# COREAON_CM_CORE register map
Vendor: Texas Instruments
Peripheral module from a debugger description file (folder omap5430_ES2_PUBLIC).
Registers are 32-bit, access per field, reset 0x30000 unless marked. A register's access mark holds for its fields unless they carry their own. Offsets are as the file gives them; lines under a group give offsets from that group; [hi:lo] are bit positions; {n}, {i} and the like mark numbered series; 'fields as' and 'values as' point back to an identical list; <NAME> marks a mode.

## COREAON_CM_CORE
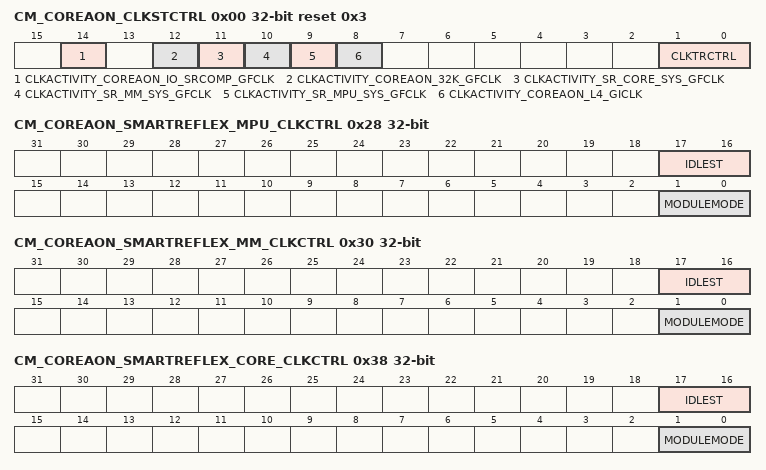
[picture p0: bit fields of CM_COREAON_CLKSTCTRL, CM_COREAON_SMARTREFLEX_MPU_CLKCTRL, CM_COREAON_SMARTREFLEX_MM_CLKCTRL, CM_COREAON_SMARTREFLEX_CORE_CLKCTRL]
0x00 CM_COREAON_CLKSTCTRL reset 0x3 — This register enables the domain power state transition. It controls the HW supervised domain power state transition between ON-ACTIVE and ON-INACTIVE states. It also holds 1 status bit per clock input of the domain.
  [14] CLKACTIVITY_COREAON_IO_SRCOMP_GFCLK ro — This field indicates the state of the COREAON_IO_SRCOMP_GFCLK clock in the domain. [warm reset insensitive] Read 0x0: Corresponding clock is definitely gated Read 0x1: Corresponding clock is running or gating/ungating transition is on-going
  [12] CLKACTIVITY_COREAON_32K_GFCLK ro — This field indicates the state of the COREAON_32K_GFCLK clock in the domain. [warm reset insensitive] Read 0x0: Corresponding clock is definitely gated Read 0x1: Corresponding clock is running or gating/ungating transition is on-going
  [11] CLKACTIVITY_SR_CORE_SYS_GFCLK ro — This field indicates the state of the SR_CORE_SYS_GFCLK clock input of the domain. [warm reset insensitive]
    0=Inact (Corresponding clock is definitely gated); 1=Act (Corresponding clock is running or gating/ungating transition is on-going)
  [10] CLKACTIVITY_SR_MM_SYS_GFCLK ro — This field indicates the state of the SR_MM_SYS_GFCLK clock input of the domain. [warm reset insensitive]
    values as CLKACTIVITY_SR_CORE_SYS_GFCLK
  [9] CLKACTIVITY_SR_MPU_SYS_GFCLK ro — This field indicates the state of the SR_MPU_SYS_GFCLK clock input of the domain. [warm reset insensitive]
    values as CLKACTIVITY_SR_CORE_SYS_GFCLK
  [8] CLKACTIVITY_COREAON_L4_GICLK ro — This field indicates the state of the COREAON_L4_GICLK clock of the domain. [warm reset insensitive]
    values as CLKACTIVITY_SR_CORE_SYS_GFCLK
  [1:0] CLKTRCTRL rw — Controls the clock state transition of the COREAON clock domain.
    0=NO_SLEEP (NO_SLEEP: Sleep transition cannot be initiated. Wakeup transition may however occur.); 2=SW_WKUP (SW_WKUP: Start a software forced wake-up transition on the domain.); 3=HW_AUTO (HW_AUTO: Automatic transition is enabled. Sleep and wakeup transition are based upon hardware conditions.)
0x28 CM_COREAON_SMARTREFLEX_MPU_CLKCTRL — This register manages the SMARTREFLEX_MPU clocks.
  [17:16] IDLEST ro — Module idle status. [warm reset insensitive]
    0=Func (Module is fully functional, including INTRCONN); 1=Trans (Module is performing transition: wakeup, or sleep, or sleep abortion); 2=Idle (Module is in Idle mode (only INTRCONN part). It is functional if using separate functional clock); 3=Disable (Module is disabled and cannot be accessed)
  [1:0] MODULEMODE rw — Control the way mandatory clocks are managed.
    0=DISABLED (Module is disable by SW. Any INTRCONN access to module results in an error, except if resulting from a module wakeup (asynchronous wakeup).); 2=ENABLE (Module is explicitly enabled. Interface clock (if not used for functions) may be gated according to the clock domain state. Functional clocks are guarantied to stay present. As long as in this configuration, power domain sleep transition cannot happen.)
0x30 CM_COREAON_SMARTREFLEX_MM_CLKCTRL — This register manages the SMARTREFLEX_MM clocks.
  fields as CM_COREAON_SMARTREFLEX_MPU_CLKCTRL
0x38 CM_COREAON_SMARTREFLEX_CORE_CLKCTRL — This register manages the SMARTREFLEX_CORE clocks.
  fields as CM_COREAON_SMARTREFLEX_MPU_CLKCTRL
0x40 CM_COREAON_USB_PHY_CORE_CLKCTRL reset 0x0 — This register manages the USB_PHY_CORE 32KHz clock.
  [8] OPTFCLKEN_CLK32K rw — Optional functional clock control.
    0=FCLK_DIS (Optional functional clock is disabled); 1=FCLK_EN (Optional functional clock is enabled)
0x50 CM_COREAON_IO_SRCOMP_CLKCTRL reset 0x0 — This register manages the clock delivered to the IO Slew rate compensation cells. [warm reset insensitive]
  [8] CLKEN_SRCOMP_FCLK rw — Functional clock control.
    0=FCLK_DIS (Functional clock is disabled); 1=FCLK_EN (Functional clock is enabled.)
